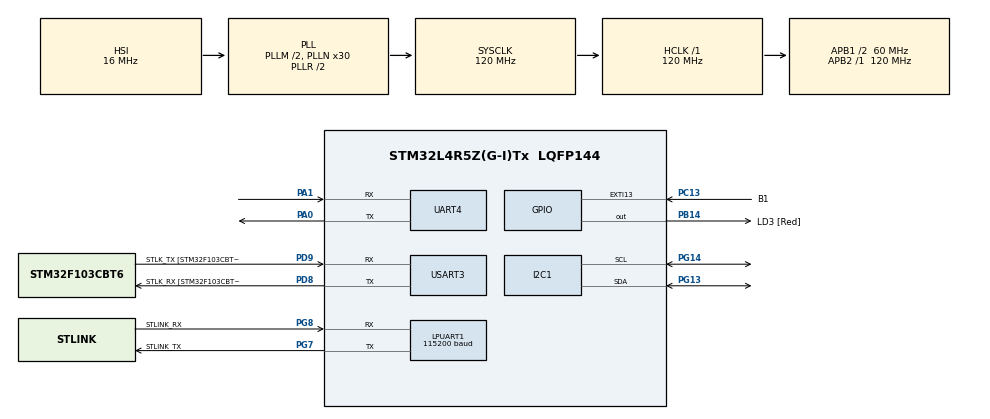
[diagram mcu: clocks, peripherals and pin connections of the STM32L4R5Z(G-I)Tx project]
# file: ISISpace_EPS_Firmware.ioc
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I2C1.Timing=0x107075B0
LPUART1.BaudRate=115200
LPUART1.WordLength=UART_WORDLENGTH_8B
Mcu.Family=STM32L4
Mcu.Name=STM32L4R5Z(G-I)Tx
Mcu.Package=LQFP144
NVIC.PriorityGroup=NVIC_PRIORITYGROUP_4
PA0.Mode=Asynchronous
PA0.Signal=UART4_TX
PA1.Mode=Asynchronous
PA1.Signal=UART4_RX
PA13\ (JTMS/SWDIO).GPIO_Label=TMS
PA13\ (JTMS/SWDIO).Mode=Trace_Asynchronous_SW
PA13\ (JTMS/SWDIO).Signal=SYS_JTMS-SWDIO
PA14\ (JTCK/SWCLK).GPIO_Label=TCK
PA14\ (JTCK/SWCLK).Mode=Trace_Asynchronous_SW
PA14\ (JTCK/SWCLK).Signal=SYS_JTCK-SWCLK
PB14.GPIO_Label=LD3 [Red]
PB14.Signal=GPIO_Output
PB3\ (JTDO/TRACESWO).GPIO_Label=SWO
PB3\ (JTDO/TRACESWO).Mode=Trace_Asynchronous_SW
PB3\ (JTDO/TRACESWO).Signal=SYS_JTDO-SWO
PC13.GPIO_Label=B1
PC13.Signal=GPXTI13
PC14-OSC32_IN\ (PC14).Mode=LSE-External-Oscillator
PC14-OSC32_IN\ (PC14).Signal=RCC_OSC32_IN
PC15-OSC32_OUT\ (PC15).Mode=LSE-External-Oscillator
PC15-OSC32_OUT\ (PC15).Signal=RCC_OSC32_OUT
PD8.GPIO_Label=STLK_RX [STM32F103CBT6_PA3]
PD8.Mode=Asynchronous
PD8.Signal=USART3_TX
PD9.GPIO_Label=STLK_TX [STM32F103CBT6_PA2]
PD9.Mode=Asynchronous
PD9.Signal=USART3_RX
PG13.Mode=I2C
PG13.Signal=I2C1_SDA
PG14.Mode=I2C
PG14.Signal=I2C1_SCL
PG7.GPIO_Label=STLINK_TX
PG7.Mode=Asynchronous
PG7.Signal=LPUART1_TX
PG8.GPIO_Label=STLINK_RX
PG8.Mode=Asynchronous
PG8.Signal=LPUART1_RX
PH0-OSC_IN\ (PH0).Signal=RCC_OSC_IN
PH1-OSC_OUT\ (PH1).Signal=RCC_OSC_OUT
ProjectManager.HeapSize=0x200
ProjectManager.StackSize=0x400
ProjectManager.TargetToolchain=STM32CubeIDE
RCC.48MHZClocksFreq_Value=24000000
RCC.ADCFreq_Value=96000000
RCC.AHBFreq_Value=120000000
RCC.APB1CLKDivider=RCC_HCLK_DIV2
RCC.APB1Freq_Value=60000000
RCC.APB1TimFreq_Value=120000000
RCC.APB2Freq_Value=120000000
RCC.APB2TimFreq_Value=120000000
RCC.CK48CLockSelection=RCC_USBCLKSOURCE_HSI48
RCC.CortexFreq_Value=120000000
RCC.HCLKFreq_Value=120000000
RCC.HSE_VALUE=8000000
RCC.HSI48_VALUE=48000000
RCC.HSI_VALUE=16000000
RCC.MSI_VALUE=4000000
RCC.PLLM1=2
RCC.PLLMUL=RCC_PLL_MUL9
RCC.PLLN=30
RCC.PLLSAI1N=12
RCC.PLLSourceVirtual=RCC_PLLSOURCE_HSI
RCC.PRESCALERUSB=RCC_USBCLKSOURCE_PLL_DIV1_5
RCC.SYSCLKFreq_VALUE=120000000
RCC.SYSCLKSource=RCC_SYSCLKSOURCE_PLLCLK
RCC.SYSCLKSourceVirtual=RCC_SYSCLKSOURCE_PLLCLK
RCC.USBFreq_Value=48000000
RCC.VCOOutputFreq_Value=240000000
UART4.FIFOMode=FIFOMODE_ENABLE
USART3.VirtualMode-Asynchronous=VM_ASYNC
board=NUCLEO-L4R5ZI

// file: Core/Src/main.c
/* USER CODE BEGIN Header */
/**
  ******************************************************************************
  * @file           : main.c
  * @brief          : Main program body
  ******************************************************************************
  * @attention
  *
  * Copyright (c) 2023 STMicroelectronics.
  * All rights reserved.
  *
  * This software is licensed under terms that can be found in the LICENSE file
  * in the root directory of this software component.
  * If no LICENSE file comes with this software, it is provided AS-IS.
  *
  ******************************************************************************
  */
/* USER CODE END Header */
#include "main.h"

I2C_HandleTypeDef hi2c1;

UART_HandleTypeDef hlpuart1;
UART_HandleTypeDef huart4;
UART_HandleTypeDef huart3;

void SystemClock_Config(void);
static void MX_GPIO_Init(void);
static void MX_LPUART1_UART_Init(void);
static void MX_USART3_UART_Init(void);
static void MX_I2C1_Init(void);
static void MX_UART4_Init(void);

int main(void)
{

  /* MCU Configuration--------------------------------------------------------*/

  /* Reset of all peripherals, Initializes the Flash interface and the Systick. */
  HAL_Init();

  /* Configure the system clock */
  SystemClock_Config();

  /* Initialize all configured peripherals */
  MX_GPIO_Init();
  MX_LPUART1_UART_Init();
  MX_USART3_UART_Init();
  MX_I2C1_Init();
  MX_UART4_Init();
  /* USER CODE BEGIN 2 */

  debug_uart_print_str("Done HAL init functions.\n");

  /* USER CODE END 2 */

  /* Infinite loop */
  while (1)
  {

    /* USER CODE BEGIN 3 */

    // dump EPS system status
    debug_uart_print_str("Start of while loop\n");

    // blink LED
    HAL_GPIO_TogglePin(GPIOB, GPIO_PIN_14);

    // I2C scan
//    debug_i2c_scan();

    /////////////////////////////////////////////////////////
    /////////////// SERVICE THE WATCHDOG ////////////////////
    /////////////////////////////////////////////////////////
    debug_uart_print_str("Executing eps_watchdog()...\n");
    eps_watchdog();

    /////////////////////////////////////////////////////////
    /////////////// GET THE SYSTEM STATUS ///////////////////
    /////////////////////////////////////////////////////////

//    eps_result_system_status_t system_status;
//    debug_uart_print_str("Fetching system status info...\n");
//    uint8_t system_status_err = eps_get_system_status(&system_status);
//
//    if (system_status_err == 0) {
//      debug_uart_print_str("System status info, no error!:\n");
//      eps_debug_uart_print_system_status(&system_status);
//    }

    /////////////////////////////////////////////////////////
    /////////////// TOGGLE A BUS GROUP //////////////////////
    /////////////////////////////////////////////////////////

//    const uint16_t CH_BF = 1<< 12;
//    const uint16_t CH_EXT_BF = 0;
//
//    debug_uart_print_str("Executing eps_output_bus_group_on( <CH12> )...\n");
//    HAL_GPIO_TogglePin(GPIOB, GPIO_PIN_7); //blue LED for bus group on
//    eps_output_bus_group_on( CH_BF,   CH_EXT_BF);
//    HAL_Delay(5000);

    /////////////////////////////////////////////////////////
    /////////////// TEST THE SYSTEM RESET ///////////////////
    /////////////////////////////////////////////////////////
//    debug_uart_print_str("Executing eps_system_reset()...\n");
//    uint8_t comms_err = eps_system_reset();
//    if (comms_err) {
//    	debug_uart_print_str("System reset status successful\n" );
//    }
//    else {
//    	debug_uart_print_str("System reset status unsuccessful\n" );
//    }
//    debug_uart_print_str("Executing eps_output_bus_group_off()...\n");
//    HAL_GPIO_TogglePin(GPIOB, GPIO_PIN_14);
//    eps_output_bus_group_off( CH_BF,  CH_EXT_BF);

    debug_uart_print_str("End of while loop\n\n");

    HAL_Delay(5000);
  }
  /* USER CODE END 3 */
}

void SystemClock_Config(void)
{
  RCC_OscInitTypeDef RCC_OscInitStruct = {0};
  RCC_ClkInitTypeDef RCC_ClkInitStruct = {0};

  /** Configure the main internal regulator output voltage
  */
  if (HAL_PWREx_ControlVoltageScaling(PWR_REGULATOR_VOLTAGE_SCALE1_BOOST) != HAL_OK)
  {
    Error_Handler();
  }

  /** Initializes the RCC Oscillators according to the specified parameters
  * in the RCC_OscInitTypeDef structure.
  */
  RCC_OscInitStruct.OscillatorType = RCC_OSCILLATORTYPE_HSI;
  RCC_OscInitStruct.HSIState = RCC_HSI_ON;
  RCC_OscInitStruct.HSICalibrationValue = RCC_HSICALIBRATION_DEFAULT;
  RCC_OscInitStruct.PLL.PLLState = RCC_PLL_ON;
  RCC_OscInitStruct.PLL.PLLSource = RCC_PLLSOURCE_HSI;
  RCC_OscInitStruct.PLL.PLLM = 2;
  RCC_OscInitStruct.PLL.PLLN = 30;
  RCC_OscInitStruct.PLL.PLLP = RCC_PLLP_DIV2;
  RCC_OscInitStruct.PLL.PLLQ = RCC_PLLQ_DIV2;
  RCC_OscInitStruct.PLL.PLLR = RCC_PLLR_DIV2;
  if (HAL_RCC_OscConfig(&RCC_OscInitStruct) != HAL_OK)
  {
    Error_Handler();
  }

  /** Initializes the CPU, AHB and APB buses clocks
  */
  RCC_ClkInitStruct.ClockType = RCC_CLOCKTYPE_HCLK|RCC_CLOCKTYPE_SYSCLK
                              |RCC_CLOCKTYPE_PCLK1|RCC_CLOCKTYPE_PCLK2;
  RCC_ClkInitStruct.SYSCLKSource = RCC_SYSCLKSOURCE_PLLCLK;
  RCC_ClkInitStruct.AHBCLKDivider = RCC_SYSCLK_DIV1;
  RCC_ClkInitStruct.APB1CLKDivider = RCC_HCLK_DIV2;
  RCC_ClkInitStruct.APB2CLKDivider = RCC_HCLK_DIV1;

  if (HAL_RCC_ClockConfig(&RCC_ClkInitStruct, FLASH_LATENCY_5) != HAL_OK)
  {
    Error_Handler();
  }
}

static void MX_I2C1_Init(void)
{

  hi2c1.Instance = I2C1;
  hi2c1.Init.Timing = 0x107075B0;
  hi2c1.Init.OwnAddress1 = 0;
  hi2c1.Init.AddressingMode = I2C_ADDRESSINGMODE_7BIT;
  hi2c1.Init.DualAddressMode = I2C_DUALADDRESS_DISABLE;
  hi2c1.Init.OwnAddress2 = 0;
  hi2c1.Init.OwnAddress2Masks = I2C_OA2_NOMASK;
  hi2c1.Init.GeneralCallMode = I2C_GENERALCALL_DISABLE;
  hi2c1.Init.NoStretchMode = I2C_NOSTRETCH_DISABLE;
  if (HAL_I2C_Init(&hi2c1) != HAL_OK)
  {
    Error_Handler();
  }

  /** Configure Analogue filter
  */
  if (HAL_I2CEx_ConfigAnalogFilter(&hi2c1, I2C_ANALOGFILTER_ENABLE) != HAL_OK)
  {
    Error_Handler();
  }

  /** Configure Digital filter
  */
  if (HAL_I2CEx_ConfigDigitalFilter(&hi2c1, 0) != HAL_OK)
  {
    Error_Handler();
  }

}

static void MX_LPUART1_UART_Init(void)
{

  hlpuart1.Instance = LPUART1;
  hlpuart1.Init.BaudRate = 115200;
  hlpuart1.Init.WordLength = UART_WORDLENGTH_8B;
  hlpuart1.Init.StopBits = UART_STOPBITS_1;
  hlpuart1.Init.Parity = UART_PARITY_NONE;
  hlpuart1.Init.Mode = UART_MODE_TX_RX;
  hlpuart1.Init.HwFlowCtl = UART_HWCONTROL_NONE;
  hlpuart1.Init.OneBitSampling = UART_ONE_BIT_SAMPLE_DISABLE;
  hlpuart1.Init.ClockPrescaler = UART_PRESCALER_DIV1;
  hlpuart1.AdvancedInit.AdvFeatureInit = UART_ADVFEATURE_NO_INIT;
  hlpuart1.FifoMode = UART_FIFOMODE_DISABLE;
  if (HAL_UART_Init(&hlpuart1) != HAL_OK)
  {
    Error_Handler();
  }
  if (HAL_UARTEx_SetTxFifoThreshold(&hlpuart1, UART_TXFIFO_THRESHOLD_1_8) != HAL_OK)
  {
    Error_Handler();
  }
  if (HAL_UARTEx_SetRxFifoThreshold(&hlpuart1, UART_RXFIFO_THRESHOLD_1_8) != HAL_OK)
  {
    Error_Handler();
  }
  if (HAL_UARTEx_DisableFifoMode(&hlpuart1) != HAL_OK)
  {
    Error_Handler();
  }

}

static void MX_UART4_Init(void)
{

  huart4.Instance = UART4;
  huart4.Init.BaudRate = 115200;
  huart4.Init.WordLength = UART_WORDLENGTH_8B;
  huart4.Init.StopBits = UART_STOPBITS_1;
  huart4.Init.Parity = UART_PARITY_NONE;
  huart4.Init.Mode = UART_MODE_TX_RX;
  huart4.Init.HwFlowCtl = UART_HWCONTROL_NONE;
  huart4.Init.OverSampling = UART_OVERSAMPLING_16;
  huart4.Init.OneBitSampling = UART_ONE_BIT_SAMPLE_DISABLE;
  huart4.Init.ClockPrescaler = UART_PRESCALER_DIV1;
  huart4.AdvancedInit.AdvFeatureInit = UART_ADVFEATURE_NO_INIT;
  if (HAL_UART_Init(&huart4) != HAL_OK)
  {
    Error_Handler();
  }
  if (HAL_UARTEx_SetTxFifoThreshold(&huart4, UART_TXFIFO_THRESHOLD_1_8) != HAL_OK)
  {
    Error_Handler();
  }
  if (HAL_UARTEx_SetRxFifoThreshold(&huart4, UART_RXFIFO_THRESHOLD_1_8) != HAL_OK)
  {
    Error_Handler();
  }
  if (HAL_UARTEx_DisableFifoMode(&huart4) != HAL_OK)
  {
    Error_Handler();
  }

}

static void MX_USART3_UART_Init(void)
{

  huart3.Instance = USART3;
  huart3.Init.BaudRate = 115200;
  huart3.Init.WordLength = UART_WORDLENGTH_8B;
  huart3.Init.StopBits = UART_STOPBITS_1;
  huart3.Init.Parity = UART_PARITY_NONE;
  huart3.Init.Mode = UART_MODE_TX_RX;
  huart3.Init.HwFlowCtl = UART_HWCONTROL_NONE;
  huart3.Init.OverSampling = UART_OVERSAMPLING_16;
  huart3.Init.OneBitSampling = UART_ONE_BIT_SAMPLE_DISABLE;
  huart3.Init.ClockPrescaler = UART_PRESCALER_DIV1;
  huart3.AdvancedInit.AdvFeatureInit = UART_ADVFEATURE_NO_INIT;
  if (HAL_UART_Init(&huart3) != HAL_OK)
  {
    Error_Handler();
  }
  if (HAL_UARTEx_SetTxFifoThreshold(&huart3, UART_TXFIFO_THRESHOLD_1_8) != HAL_OK)
  {
    Error_Handler();
  }
  if (HAL_UARTEx_SetRxFifoThreshold(&huart3, UART_RXFIFO_THRESHOLD_1_8) != HAL_OK)
  {
    Error_Handler();
  }
  if (HAL_UARTEx_DisableFifoMode(&huart3) != HAL_OK)
  {
    Error_Handler();
  }

}

static void MX_GPIO_Init(void)
{
  GPIO_InitTypeDef GPIO_InitStruct = {0};

  /* GPIO Ports Clock Enable */
  __HAL_RCC_GPIOC_CLK_ENABLE();
  __HAL_RCC_GPIOH_CLK_ENABLE();
  __HAL_RCC_GPIOA_CLK_ENABLE();
  __HAL_RCC_GPIOB_CLK_ENABLE();
  __HAL_RCC_GPIOD_CLK_ENABLE();
  __HAL_RCC_GPIOG_CLK_ENABLE();
  HAL_PWREx_EnableVddIO2();

  /*Configure GPIO pin Output Level */
  HAL_GPIO_WritePin(LD3_GPIO_Port, LD3_Pin, GPIO_PIN_RESET);

  /*Configure GPIO pin : B1_Pin */
  GPIO_InitStruct.Pin = B1_Pin;
  GPIO_InitStruct.Mode = GPIO_MODE_IT_RISING;
  GPIO_InitStruct.Pull = GPIO_NOPULL;
  HAL_GPIO_Init(B1_GPIO_Port, &GPIO_InitStruct);

  /*Configure GPIO pin : LD3_Pin */
  GPIO_InitStruct.Pin = LD3_Pin;
  GPIO_InitStruct.Mode = GPIO_MODE_OUTPUT_PP;
  GPIO_InitStruct.Pull = GPIO_NOPULL;
  GPIO_InitStruct.Speed = GPIO_SPEED_FREQ_LOW;
  HAL_GPIO_Init(LD3_GPIO_Port, &GPIO_InitStruct);

}

void Error_Handler(void)
{
  __disable_irq();
  while (1)
  {
  }
}
